AUTOSAR XML (schema 4.0)
package /MotorDriverComponent
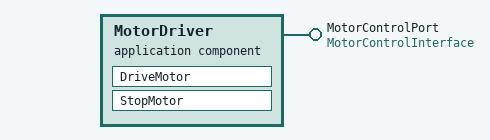
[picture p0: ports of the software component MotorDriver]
  application software component type MotorDriver
    provide port MotorControlPort: required-interface=MotorControlInterface
    internal behavior MotorDriverBehavior
      runnable DriveMotor
      runnable StopMotor
